# MINI51AN_v1 register map
File version: 1.0
Registers are 32-bit, read-write, reset 0x0 unless marked. A register's access mark holds for its fields unless they carry their own. Offsets are from the block's base; [hi:lo] are bit positions; {n}, {i} and the like mark numbered series; 'fields as' and 'values as' point back to an identical list.

## GP — GP Register Map
Base 0x50004000
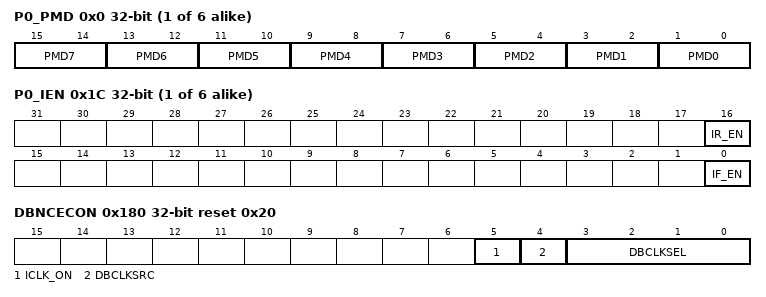
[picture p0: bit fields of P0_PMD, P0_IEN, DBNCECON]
{0x0+0x40*i} P{i}_PMD (reset mask 0xFFFF0000) (i=0..5) — P{i} Pin I/O Mode Control
  [2n+1:2n] PMD{n} (n=0..7) — Px Pin[n] I/O Mode Control
{0x4+0x40*i} P{i}_OFFD (i=0..5) — P{i} Pin OFF Digital Enable
  [23:16] OFFD — OFFD: Px Pin[n] OFF Digital Input Path Enable
    0=I/O digital input path Enabled; 1=I/O digital input path Disabled (digital input tied to low)
{0x8+0x40*i} P{i}_DOUT reset 0xF3 (i=0..5) — P{i} Data Output Value
  [0] DOUT — Px Pin[n] Output Value. Each of these bits controls the status of a Px pin when the Px pin is configures as output, open-drain and quasi-mode.
    0=Px pin[n] will drive Low if the corresponding output mode enabling bit is set; 1=Px pin[n] will drive High if the corresponding output mode enabling bit is set
{0xC+0x40*i} P{i}_DMASK (i=0..5) — P{i} Data Output Write Mask
  [0] DMASK — Px Data Output Write Mask. These bits are used to protect the corresponding register of Px_DOUT pin[n]. When the DMASK bit[n] is set to 1, the corresponding DOUTn pin is protected. The write signal is masked, and writing data to the protect pin is ignored.
    0=The corresponding Px_DOUT[n] bit can be updated; 1=The corresponding Px_DOUT[n] bit is protected
{0x10+0x40*i} P{i}_PIN ro (reset mask 0xFFFFFF00) (i=0..5) — P{i} Pin Value
  [0] PIN — Px Pin[n] Value
{0x14+0x40*i} P{i}_DBEN (i=0..5) — P{i} De-bounce Enable
  [0] DBEN — Px Input Signal De-bounce Enable. DBEN[n] is used to enable the de-bounce function for each corresponding bit. If the input signal pulse width can't be sampled by continuous two de-bounce sample cycle, the input signal transition is regarded as the signal bounce and will not trigger the interrupt. The DBEN[n] is used for "edge-trigger" interrupt only, and is ignored for "level trigger" interrupt.
    0=The pin[n] de-bounce function disabled; 1=The pin[n] de-bounce function enabled
{0x18+0x40*i} P{i}_IMD (i=0..5) — P{i} Interrupt Mode Control
  [0] IMD — Port 0-5 Interrupt Mode Control. IMD[n] is used to control the interrupt by level trigger or edge trigger. If the interrupt is by edge trigger, the trigger source is control de-bounced. If the interrupt is by level trigger, the input source is sampled by one clock and then generates the interrupt.
    0=Edge trigger interrupt; 1=Level trigger interrupt
{0x1C+0x40*i} P{i}_IEN (i=0..5) — P{i} Interrupt Enable
  [16] IR_EN — Port 0-5 Interrupt Enable by Input Rising Edge or Input Level High. IR_EN[n] is used to enable the interrupt for each of the corresponding input Px[n]. Setting bit to 1 also enables the pin wake-up function. When the IR_EN[n] bit is set to 1: If the interrupt is level mode trigger, the input Px[n] state at level "high" will generate the interrupt. If the interrupt is edge mode trigger, the input Px[n] state changed from "low-to-high" will generate the interrupt.
    0=The Px[n] level-high or low-to-high interrupt Disabled; 1=The Px[n] level-high or low-to-high interrupt Enabled
  [0] IF_EN — Port 0-5 Interrupt Enable by Input Falling Edge or Input Level Low. IF_EN[n] is used to enable the interrupt for each of the corresponding input Px[n]. Setting bit to 1 also enables the pin wake-up function. When the IF_EB[n] bit is set to 1: If the interrupt is level mode trigger, the input Px[n] state at level "low" will generate the interrupt. If the interrupt is edge mode trigger, the input Px[n] state changed from "high-to-low" will generate the interrupt.
    0=The Px[n] state low-level or high-to-low change interrupt Disabled; 1=The Px[n] state low-level or high-to-low change interrupt Enabled
{0x20+0x40*i} P{i}_ISRC (i=0..5) — P{i} Interrupt Trigger Source Indicator
  [0] ISRC — Port 0-5 Interrupt Trigger Source Indicator. Read :
    0=No interrupt at Px[n]. No action; 1=Indicates Px[n] generate an interrupt. Clear the corresponding pending interrupt
0x180 DBNCECON reset 0x20 — Interrupt De-bounce Cycle Control
  [5] ICLK_ON — Interrupt Clock On Mode. Setting this bit to 0 will disable the interrupt generate circuit clock, if the pin[n] interrupt is disabled.
    0=The clock Disabled if the P0/1/2/3/4[n] interrupt is disabled; 1=Interrupt generated circuit clock always Enabled
  [4] DBCLKSRC — De-bounce Counter Clock Source Selection
    0=De-bounce counter clock source is the HCLK; 1=De-bounce counter clock source is the internal 10 kHz clock
  [3:0] DBCLKSEL — De-bounce Sampling Cycle Selection
0x200 P00_DOUT reset 0x1 — P0.0 Data Output Value
  [0] P_DOUT — P[x][n] I/O Pin Bit Output/Input Control. Writing this bit can control one GPIO pin output value.
    0=The corresponding GPIO pin set to low. Corresponding GPIO pin status is low; 1=The corresponding GPIO pin set to high. Corresponding GPIO pin status is high
0x204 P01_DOUT reset 0x1 — P0.1 Data Output Value
  fields as P00_DOUT
0x210 P04_DOUT reset 0x1 — P0.4 Data Output Value
  fields as P00_DOUT
0x214 P05_DOUT reset 0x1 — P0.5 Data Output Value
  fields as P00_DOUT
0x218 P06_DOUT reset 0x1 — P0.6 Data Output Value
  fields as P00_DOUT
0x21C P07_DOUT reset 0x1 — P0.7 Data Output Value
  fields as P00_DOUT
0x220 P10_DOUT reset 0x1 — P1.0 Data Output Value
  fields as P00_DOUT
0x228 P12_DOUT reset 0x1 — P1.2 Data Output Value
  fields as P00_DOUT
0x22C P13_DOUT reset 0x1 — P1.3 Data Output Value
  fields as P00_DOUT
0x230 P14_DOUT reset 0x1 — P1.4 Data Output Value
  fields as P00_DOUT
0x234 P15_DOUT reset 0x1 — P1.5 Data Output Value
  fields as P00_DOUT
0x248 P22_DOUT reset 0x1 — P2.2 Data Output Value
  fields as P00_DOUT
0x24C P23_DOUT reset 0x1 — P2.3 Data Output Value
  fields as P00_DOUT
0x250 P24_DOUT reset 0x1 — P2.4 Data Output Value
  fields as P00_DOUT
0x254 P25_DOUT reset 0x1 — P2.5 Data Output Value
  fields as P00_DOUT
0x258 P26_DOUT reset 0x1 — P2.6 Data Output Value
  fields as P00_DOUT
0x260 P30_DOUT reset 0x1 — P3.0 Data Output Value
  fields as P00_DOUT
0x264 P31_DOUT reset 0x1 — P3.1 Data Output Value
  fields as P00_DOUT
0x268 P32_DOUT reset 0x1 — P3.2 Data Output Value
  fields as P00_DOUT
0x270 P34_DOUT reset 0x1 — P3.4 Data Output Value
  fields as P00_DOUT
0x274 P35_DOUT reset 0x1 — P3.5 Data Output Value
  fields as P00_DOUT
0x278 P36_DOUT reset 0x1 — P3.6 Data Output Value
  fields as P00_DOUT
0x298 P46_DOUT reset 0x1 — P4.6 Data Output Value
  fields as P00_DOUT
0x29C P47_DOUT reset 0x1 — P4.7 Data Output Value
  fields as P00_DOUT
0x2A0 P50_DOUT reset 0x1 — P5.0 Data Output Value
  fields as P00_DOUT
0x2A4 P51_DOUT reset 0x1 — P5.1 Data Output Value
  fields as P00_DOUT
0x2A8 P52_DOUT reset 0x1 — P5.2 Data Output Value
  fields as P00_DOUT
0x2AC P53_DOUT reset 0x1 — P5.3 Data Output Value
  fields as P00_DOUT
0x2B0 P54_DOUT reset 0x1 — P5.4 Data Output Value
  fields as P00_DOUT
0x2B4 P55_DOUT reset 0x1 — P5.5 Data Output Value
  fields as P00_DOUT
